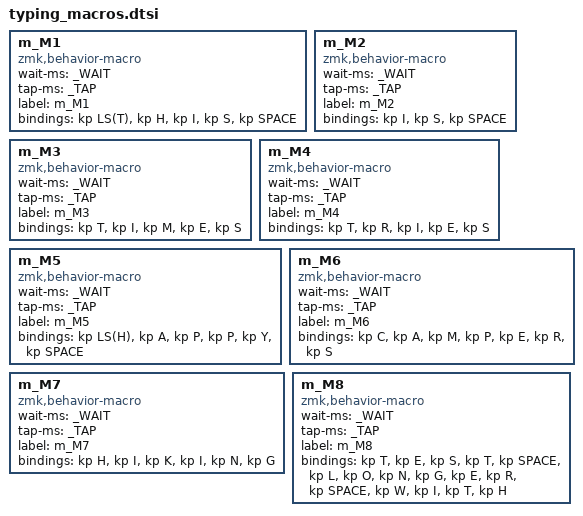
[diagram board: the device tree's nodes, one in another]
#include <dt-bindings/zmk/keys.h>

/* ************************************************** */
/* TEST macros to futz with settings in batches and string helpers
    tries with Shift and with Punctuation and spaces...
    [ ] does separating keys inside bindings= expression matter?
*/

#define _WAIT <5>
#define _TAP <5>

m_M1: m_M1 {
    wait-ms = _WAIT;
    tap-ms = _TAP;
    compatible = "zmk,behavior-macro";
    label = "m_M1";
    #binding-cells = <0>;
    bindings = <&kp LS(T) &kp H &kp I &kp S &kp SPACE>;
};

m_M2: m_M2 {
    wait-ms = _WAIT;
    tap-ms = _TAP;
    compatible = "zmk,behavior-macro";
    label = "m_M2";
    #binding-cells = <0>;
    bindings = <&kp I>, <&kp S>, <&kp SPACE>;
};

m_M3: m_M3 {
    wait-ms = _WAIT;
    tap-ms = _TAP;
    compatible = "zmk,behavior-macro";
    label = "m_M3";
    #binding-cells = <0>;
    bindings = <&kp T &kp I &kp M &kp E &kp S>;
};

m_M4: m_M4 {
    wait-ms = _WAIT;
    tap-ms = _TAP;
    compatible = "zmk,behavior-macro";
    label = "m_M4";
    #binding-cells = <0>;
    bindings = <&kp T &kp R &kp I &kp E &kp S>;
};

m_M5: m_M5 {
    wait-ms = _WAIT;
    tap-ms = _TAP;
    compatible = "zmk,behavior-macro";
    label = "m_M5";
    #binding-cells = <0>;
    bindings = <&kp LS(H) &kp A &kp P &kp P &kp Y &kp SPACE>;
};

m_M6: m_M6 {
    wait-ms = _WAIT;
    tap-ms = _TAP;
    compatible = "zmk,behavior-macro";
    label = "m_M6";
    #binding-cells = <0>;
    bindings = <&kp C &kp A &kp M &kp P &kp E &kp R &kp S>;
};

m_M7: m_M7 {
    wait-ms = _WAIT;
    tap-ms = _TAP;
    compatible = "zmk,behavior-macro";
    label = "m_M7";
    #binding-cells = <0>;
    bindings = <&kp H &kp I &kp K &kp I &kp N &kp G>;
};

m_M8: m_M8 {
    wait-ms = _WAIT;
    tap-ms = _TAP;
    compatible = "zmk,behavior-macro";
    label = "m_M8";
    #binding-cells = <0>;
    bindings = <&kp T &kp E &kp S &kp T &kp SPACE &kp L &kp O &kp N &kp G &kp E &kp R &kp SPACE &kp W &kp I &kp T &kp H>;
};

